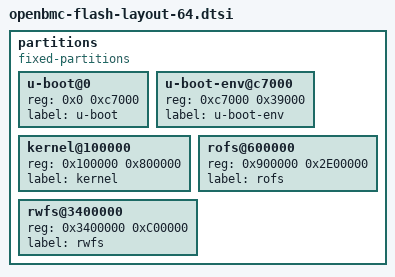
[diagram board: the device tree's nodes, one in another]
// SPDX-License-Identifier: GPL-2.0+
/*
 * Copyright (C) 2020 Bytedance.
 */

partitions {
	compatible = "fixed-partitions";
	#address-cells = <1>;
	#size-cells = <1>;

	u-boot@0 {
		reg = <0x0 0xc7000>;
		label = "u-boot";
	};

	u-boot-env@c7000 {
		reg = <0xc7000 0x39000>;
		label = "u-boot-env";
	};

	kernel@100000 {
		reg = <0x100000 0x800000>;
		label = "kernel";
	};

	rofs@600000 {
		reg = <0x900000 0x2E00000>;
		label = "rofs";
	};

	rwfs@3400000 {
		reg = <0x3400000 0xC00000>;
		label = "rwfs";
	};
};
